AUTOSAR XML (schema 4-0-3)
standard types defined: Boolean, uint8, UInt16, UInt32, UInt8
package /AUTOSAR_Platform/DataConstrs
  range DC_Boolean: raw 0..1
  range DC_UInt16: raw 0..65535
  range DC_UInt8: raw 0..255
package /PATAC/Facility/DataTypes/Implementation
  compu method COMPU_Boolean: 0=FALSE, 1=TRUE
  unit NoUnit: factor-si-to-unit=1, offset-si-to-unit=0
package /PATAC/MSM/ComponentTypes
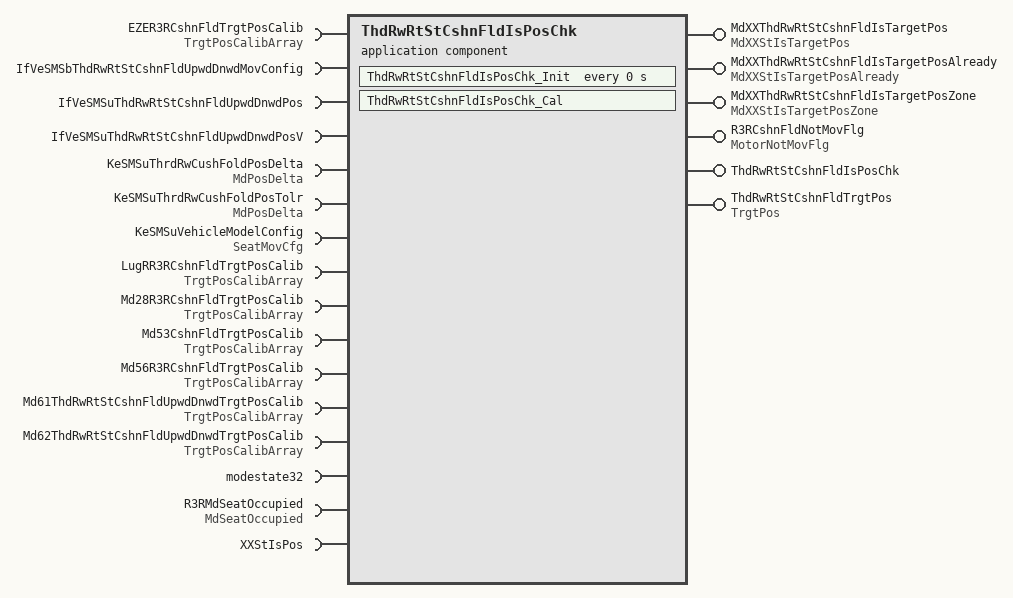
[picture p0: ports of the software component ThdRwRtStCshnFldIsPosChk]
  application sw component type ThdRwRtStCshnFldIsPosChk
    6 x provide port:
      MdXXThdRwRtStCshnFldIsTargetPos: nonqueued-sender-com-spec=data-element=MdXXStIsTargetPos/Val, provided-interface=MdXXStIsTargetPos
      MdXXThdRwRtStCshnFldIsTargetPosAlready: nonqueued-sender-com-spec=data-element=MdXXStIsTargetPosAlready/Val, provided-interface=MdXXStIsTargetPosAlready
      MdXXThdRwRtStCshnFldIsTargetPosZone: nonqueued-sender-com-spec=data-element=MdXXStIsTargetPosZone/Val, provided-interface=MdXXStIsTargetPosZone
      R3RCshnFldNotMovFlg: nonqueued-sender-com-spec{data-element=MotorNotMovFlg/Val, init-value=0}, provided-interface=MotorNotMovFlg
      ThdRwRtStCshnFldIsPosChk: server-com-spec{operation=Cal, queue-length=1}, provided-interface=ThdRwRtStCshnFldIsPosChk
      ThdRwRtStCshnFldTrgtPos: nonqueued-sender-com-spec{data-element=TrgtPos/Val, init-value=4095}, provided-interface=TrgtPos
    16 x require port:
      EZER3RCshnFldTrgtPosCalib: nonqueued-receiver-com-spec{data-element=TrgtPosArray, filter=data-filter-type=ALWAYS, init-value=[4095, 4095, 4095]}, required-interface=TrgtPosCalibArray
      IfVeSMSbThdRwRtStCshnFldUpwdDnwdMovConfig: nonqueued-receiver-com-spec{data-element=IfVeSMSbThdRwRtStCshnFldUpwdDnwdMovConfig/Val, filter=data-filter-type=ALWAYS, init-value=0}, required-interface=IfVeSMSbThdRwRtStCshnFldUpwdDnwdMovConfig
      IfVeSMSuThdRwRtStCshnFldUpwdDnwdPos: nonqueued-receiver-com-spec{data-element=IfVeSMSuThdRwRtStCshnFldUpwdDnwdPos/Val, filter=data-filter-type=ALWAYS, init-value=0}, required-interface=IfVeSMSuThdRwRtStCshnFldUpwdDnwdPos
      IfVeSMSuThdRwRtStCshnFldUpwdDnwdPosV: nonqueued-receiver-com-spec{data-element=IfVeSMSuThdRwRtStCshnFldUpwdDnwdPosV/Val, filter=data-filter-type=ALWAYS, init-value=0}, required-interface=IfVeSMSuThdRwRtStCshnFldUpwdDnwdPosV
      KeSMSuThrdRwCushFoldPosDelta: parameter-require-com-spec{init-value=150, parameter=MdPosDelta/Val}, required-interface=MdPosDelta
      KeSMSuThrdRwCushFoldPosTolr: parameter-require-com-spec{init-value=150, parameter=MdPosDelta/Val}, required-interface=MdPosDelta
      KeSMSuVehicleModelConfig: parameter-require-com-spec{init-value=2, parameter=SeatMovCfg/Val}, required-interface=SeatMovCfg
      LugRR3RCshnFldTrgtPosCalib: nonqueued-receiver-com-spec{data-element=TrgtPosArray, filter=data-filter-type=ALWAYS, init-value=[4095, 4095, 4095]}, required-interface=TrgtPosCalibArray
      Md28R3RCshnFldTrgtPosCalib: nonqueued-receiver-com-spec{data-element=TrgtPosArray, filter=data-filter-type=ALWAYS, init-value=[4095, 4095, 4095]}, required-interface=TrgtPosCalibArray
      Md53CshnFldTrgtPosCalib: nonqueued-receiver-com-spec{data-element=TrgtPosArray, filter=data-filter-type=ALWAYS, init-value=[4095, 4095, 4095]}, required-interface=TrgtPosCalibArray
      Md56R3RCshnFldTrgtPosCalib: nonqueued-receiver-com-spec{data-element=TrgtPosArray, filter=data-filter-type=ALWAYS, init-value=[4095, 4095, 4095]}, required-interface=TrgtPosCalibArray
      Md61ThdRwRtStCshnFldUpwdDnwdTrgtPosCalib: nonqueued-receiver-com-spec{data-element=TrgtPosArray, filter=data-filter-type=ALWAYS, init-value=[4095, 4095, 4095]}, required-interface=TrgtPosCalibArray
      Md62ThdRwRtStCshnFldUpwdDnwdTrgtPosCalib: nonqueued-receiver-com-spec{data-element=TrgtPosArray, filter=data-filter-type=ALWAYS, init-value=[4095, 4095, 4095]}, required-interface=TrgtPosCalibArray
      modestate32: nonqueued-receiver-com-spec{data-element=modestate32/Val, filter=data-filter-type=ALWAYS, init-value=0}, required-interface=modestate32
      R3RMdSeatOccupied: nonqueued-receiver-com-spec{data-element=MdSeatOccupied/Val, filter=data-filter-type=ALWAYS, init-value=0}, required-interface=MdSeatOccupied
      XXStIsPos: client-com-spec=Get, required-interface=XXStIsPos
    behavior ThdRwRtStCshnFldIsPosChk_InternalBehavior
      operation invoked event OIT_ThdRwRtStCshnFldIsPosChk_Cal_ThdRwRtStCshnFldIsPosChk_Cal: start-on-event=ThdRwRtStCshnFldIsPosChk_Cal, operation=ThdRwRtStCshnFldIsPosChk.Cal
      timing event ThdRwRtStCshnFldIsPosChk_InitEvent: start-on-event=ThdRwRtStCshnFldIsPosChk_Init, period=0
      runnable ThdRwRtStCshnFldIsPosChk_Cal
        data-receive-point-by-arguments:
          12 x access:
            REC_EZER3RCshnFldTrgtPosCalib_TrgtPosArray: accessed-variable=EZER3RCshnFldTrgtPosCalib.TrgtPosArray
            REC_IfVeSMSbThdRwRtStCshnFldUpwdDnwdMovConfig_Val: accessed-variable=IfVeSMSbThdRwRtStCshnFldUpwdDnwdMovConfig.Val
            REC_IfVeSMSuThdRwRtStCshnFldUpwdDnwdPos_Val: accessed-variable=IfVeSMSuThdRwRtStCshnFldUpwdDnwdPos.Val
            REC_IfVeSMSuThdRwRtStCshnFldUpwdDnwdPosV_Val: accessed-variable=IfVeSMSuThdRwRtStCshnFldUpwdDnwdPosV.Val
            REC_LugRR3RCshnFldTrgtPosCalib_TrgtPosArray: accessed-variable=LugRR3RCshnFldTrgtPosCalib.TrgtPosArray
            REC_Md28R3RCshnFldTrgtPosCalib_TrgtPosArray: accessed-variable=Md28R3RCshnFldTrgtPosCalib.TrgtPosArray
            REC_Md53CshnFldTrgtPosCalib_TrgtPosArray: accessed-variable=Md53CshnFldTrgtPosCalib.TrgtPosArray
            REC_Md56R3RCshnFldTrgtPosCalib_TrgtPosArray: accessed-variable=Md56R3RCshnFldTrgtPosCalib.TrgtPosArray
            REC_Md61ThdRwRtStCshnFldUpwdDnwdTrgtPosCalib_TrgtPosArray: accessed-variable=Md61ThdRwRtStCshnFldUpwdDnwdTrgtPosCalib.TrgtPosArray
            REC_Md62ThdRwRtStCshnFldUpwdDnwdTrgtPosCalib_TrgtPosArray: accessed-variable=Md62ThdRwRtStCshnFldUpwdDnwdTrgtPosCalib.TrgtPosArray
            REC_modestate32_Val: accessed-variable=modestate32.Val
            REC_R3RMdSeatOccupied_Val: accessed-variable=R3RMdSeatOccupied.Val
        data-send-points:
          5 x access:
            SEND_MdXXThdRwRtStCshnFldIsTargetPos_Val: accessed-variable=MdXXThdRwRtStCshnFldIsTargetPos.Val
            SEND_MdXXThdRwRtStCshnFldIsTargetPosAlready_Val: accessed-variable=MdXXThdRwRtStCshnFldIsTargetPosAlready.Val
            SEND_MdXXThdRwRtStCshnFldIsTargetPosZone_Val: accessed-variable=MdXXThdRwRtStCshnFldIsTargetPosZone.Val
            SEND_R3RCshnFldNotMovFlg_Val: accessed-variable=R3RCshnFldNotMovFlg.Val
            SEND_ThdRwRtStCshnFldTrgtPos_Val: accessed-variable=ThdRwRtStCshnFldTrgtPos.Val
        parameter access PA_KeSMSuThrdRwCushFoldPosDelta_Val: accessed-parameter=KeSMSuThrdRwCushFoldPosDelta.Val
        parameter access PA_KeSMSuThrdRwCushFoldPosTolr_Val: accessed-parameter=KeSMSuThrdRwCushFoldPosTolr.Val
        parameter access PA_KeSMSuVehicleModelConfig_Val: accessed-parameter=KeSMSuVehicleModelConfig.Val
        sync call SC_XXStIsPos_Get: operation=XXStIsPos.Get, timeout=0
      runnable ThdRwRtStCshnFldIsPosChk_Init
        parameter access PA_KeSMSuThrdRwCushFoldPosDelta_Val: accessed-parameter=KeSMSuThrdRwCushFoldPosDelta.Val
        parameter access PA_KeSMSuThrdRwCushFoldPosTolr_Val: accessed-parameter=KeSMSuThrdRwCushFoldPosTolr.Val
        parameter access PA_KeSMSuVehicleModelConfig_Val: accessed-parameter=KeSMSuVehicleModelConfig.Val
  swc implementation ThdRwRtStCshnFldIsPosChk_Implementation: behavior=ThdRwRtStCshnFldIsPosChk_InternalBehavior
    code-descriptors:
      code Default: artifact-descriptors=autosar-engineering-object={short-label=Default, category=SWSRC}
package /PATAC/MSM/DataTypes
  parameter interface SeatMovCfg
    parameter data prototype Val: sw-calibration-access=READ-WRITE, type=UInt8
package /PATAC/MSM/ModeAdjust/CalPortInterface
  parameter interface MdPosDelta
    parameter data prototype Val: sw-calibration-access=READ-WRITE, type=UInt16
package /PATAC/MSM/ModeAdjust/DataType
  impl type TrgtPosCalibArray: category=ARRAY, sw-calibration-access=READ-ONLY, type-emitter=RTE  # 0:pos 1:max 2:min
    element Element: array-size=3, array-size-semantics=FIXED-SIZE, implementation-data-type=UInt16, invalid-value=0
package /PATAC/MSM/ModeAdjust/Interfaces
  sender receiver interface IfVeSMSuThdRwRtStCshnFldUpwdDnwdPos: invalidation-policy{data-element=IfVeSMSuThdRwRtStCshnFldUpwdDnwdPos/Val, handle-invalid=DONT-INVALIDATE}
    data Val: type=UInt16
  sender receiver interface IfVeSMSuThdRwRtStCshnFldUpwdDnwdPosV: invalidation-policy{data-element=IfVeSMSuThdRwRtStCshnFldUpwdDnwdPosV/Val, handle-invalid=DONT-INVALIDATE}
    data Val: type=Implementation/Boolean
package /PATAC/MSM/ModeAdjust/PortInterface
  client server interface ThdRwRtStCshnFldIsPosChk
    operation Cal
  client server interface XXStIsPos
    operation Get
      8 x arg, all with server-argument-impl-policy=USE-ARGUMENT-TYPE:
        PosV: type=DataTypes/Boolean, direction=IN
        Pos: type=UInt16, direction=IN
        CalibArray: type=TrgtPosCalibArray, direction=IN
        Delta: type=UInt16, direction=IN
        Tolr: type=UInt16, direction=IN
        IsPos: type=DataTypes/Boolean, direction=OUT
        IsPosZone: type=DataTypes/Boolean, direction=OUT
        IsPosAlready: type=DataTypes/Boolean, direction=OUT
  7 x sender receiver interface:
    MdSeatOccupied: invalidation-policy{data-element=MdSeatOccupied/Val, handle-invalid=DONT-INVALIDATE}
      data Val: type=Implementation/Boolean
    MdXXStIsTargetPos: invalidation-policy{data-element=MdXXStIsTargetPos/Val, handle-invalid=DONT-INVALIDATE}
      data Val: type=UInt32
    MdXXStIsTargetPosAlready: invalidation-policy{data-element=MdXXStIsTargetPosAlready/Val, handle-invalid=DONT-INVALIDATE}
      data Val: type=UInt32
    MdXXStIsTargetPosZone: invalidation-policy{data-element=MdXXStIsTargetPosZone/Val, handle-invalid=DONT-INVALIDATE}
      data Val: type=UInt32
    modestate32: invalidation-policy{data-element=modestate32/Val, handle-invalid=DONT-INVALIDATE}
      data Val: type=UInt32
    MotorNotMovFlg: invalidation-policy{data-element=MotorNotMovFlg/Val, handle-invalid=DONT-INVALIDATE}
      data Val: type=Implementation/Boolean
    TrgtPosCalibArray: invalidation-policy{data-element=TrgtPosArray, handle-invalid=DONT-INVALIDATE}
      data TrgtPosArray: type=TrgtPosCalibArray  # 0:Pos 1:Max 2:Min
package /PATAC/MSM/PortInterfaces
  sender receiver interface IfVeSMSbThdRwRtStCshnFldUpwdDnwdMovConfig: invalidation-policy{data-element=IfVeSMSbThdRwRtStCshnFldUpwdDnwdMovConfig/Val, handle-invalid=DONT-INVALIDATE}
    data Val: type=Implementation/Boolean
  sender receiver interface TrgtPos: invalidation-policy{data-element=TrgtPos/Val, handle-invalid=DONT-INVALIDATE}
    data Val: type=UInt16
